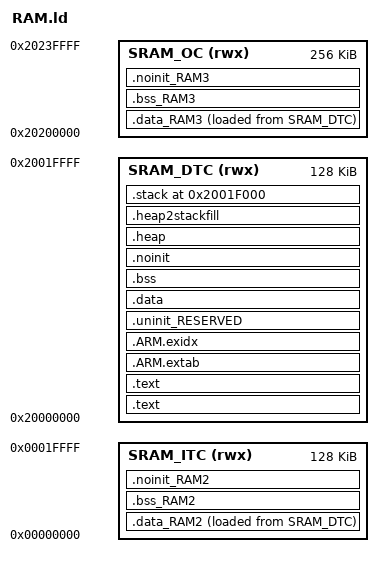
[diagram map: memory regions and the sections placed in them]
/*
 * GENERATED FILE - DO NOT EDIT
 * Copyright (c) 2008-2013 Code Red Technologies Ltd,
 * Copyright 2015, 2018-2019 NXP
 * (c) NXP Semiconductors 2013-2019
 * Generated linker script file for MIMXRT1052xxxxB
 * Created from linkscript.ldt by FMCreateLinkLibraries
 * Using Freemarker v2.3.23
 * MCUXpresso IDE v11.0.0 [Build 2516] [2019-06-05] on Oct 3, 2019 3:25:30 PM
 */

/*
INCLUDE "MIMXRT1052_RAM_Debug_library.ld"
  Created error with: "libcr_newlib_semihost.a"
*/
GROUP (
  "libgcc.a"
  "libc_nano.a"
  "libm.a"
)

/*
INCLUDE "MIMXRT1052_RAM_Debug_memory.ld"
*/
MEMORY
{
  /* Define each memory region */
  SRAM_DTC (rwx) : ORIGIN = 0x20000000, LENGTH = 0x20000 /* 128K bytes (alias RAM) */  
  SRAM_ITC (rwx) : ORIGIN = 0x0, LENGTH = 0x20000 /* 128K bytes (alias RAM2) */  
  SRAM_OC (rwx) : ORIGIN = 0x20200000, LENGTH = 0x40000 /* 256K bytes (alias RAM3) */  
}

  /* Define a symbol for the top of each memory region */
  __base_SRAM_DTC = 0x20000000  ; /* SRAM_DTC */  
  __base_RAM = 0x20000000 ; /* RAM */  
  __top_SRAM_DTC = 0x20000000 + 0x20000 ; /* 128K bytes */  
  __top_RAM = 0x20000000 + 0x20000 ; /* 128K bytes */  
  __base_SRAM_ITC = 0x0  ; /* SRAM_ITC */  
  __base_RAM2 = 0x0 ; /* RAM2 */  
  __top_SRAM_ITC = 0x0 + 0x20000 ; /* 128K bytes */  
  __top_RAM2 = 0x0 + 0x20000 ; /* 128K bytes */  
  __base_SRAM_OC = 0x20200000  ; /* SRAM_OC */  
  __base_RAM3 = 0x20200000 ; /* RAM3 */  
  __top_SRAM_OC = 0x20200000 + 0x40000 ; /* 256K bytes */  
  __top_RAM3 = 0x20200000 + 0x40000 ; /* 256K bytes */  





ENTRY(ResetISR)

SECTIONS
{
     /* MAIN TEXT SECTION */
    .text : ALIGN(4)
    {
        FILL(0xff)
        __vectors_start__ = ABSOLUTE(.) ;
        KEEP(*(.isr_vector))
        /* Global Section Table */
        . = ALIGN(4) ;
        __section_table_start = .;
        __data_section_table = .;
        LONG(LOADADDR(.data));
        LONG(    ADDR(.data));
        LONG(  SIZEOF(.data));
        LONG(LOADADDR(.data_RAM2));
        LONG(    ADDR(.data_RAM2));
        LONG(  SIZEOF(.data_RAM2));
        LONG(LOADADDR(.data_RAM3));
        LONG(    ADDR(.data_RAM3));
        LONG(  SIZEOF(.data_RAM3));
        __data_section_table_end = .;
        __bss_section_table = .;
        LONG(    ADDR(.bss));
        LONG(  SIZEOF(.bss));
        LONG(    ADDR(.bss_RAM2));
        LONG(  SIZEOF(.bss_RAM2));
        LONG(    ADDR(.bss_RAM3));
        LONG(  SIZEOF(.bss_RAM3));
        __bss_section_table_end = .;
        __section_table_end = . ;
        /* End of Global Section Table */

        *(.after_vectors*)

    } > SRAM_DTC

    .text : ALIGN(4)
    {
       *(.text*)
       *(.rodata .rodata.* .constdata .constdata.*)
       . = ALIGN(4);
    } > SRAM_DTC
    /*
     * for exception handling/unwind - some Newlib functions (in common
     * with C++ and STDC++) use this. 
     */
    .ARM.extab : ALIGN(4) 
    {
        *(.ARM.extab* .gnu.linkonce.armextab.*)
    } > SRAM_DTC

    __exidx_start = .;

    .ARM.exidx : ALIGN(4)
    {
        *(.ARM.exidx* .gnu.linkonce.armexidx.*)
    } > SRAM_DTC
    __exidx_end = .;
 
    _etext = .;
        
    /* DATA section for SRAM_ITC */

    .data_RAM2 : ALIGN(4)
    {
        FILL(0xff)
        PROVIDE(__start_data_RAM2 = .) ;
        *(.ramfunc.$RAM2)
        *(.ramfunc.$SRAM_ITC)
        *(.data.$RAM2)
        *(.data.$SRAM_ITC)
        *(.data.$RAM2.*)
        *(.data.$SRAM_ITC.*)
        . = ALIGN(4) ;
        PROVIDE(__end_data_RAM2 = .) ;
     } > SRAM_ITC AT>SRAM_DTC
    /* DATA section for SRAM_OC */

    .data_RAM3 : ALIGN(4)
    {
        FILL(0xff)
        PROVIDE(__start_data_RAM3 = .) ;
        *(.ramfunc.$RAM3)
        *(.ramfunc.$SRAM_OC)
        *(.data.$RAM3)
        *(.data.$SRAM_OC)
        *(.data.$RAM3.*)
        *(.data.$SRAM_OC.*)
        . = ALIGN(4) ;
        PROVIDE(__end_data_RAM3 = .) ;
     } > SRAM_OC AT>SRAM_DTC
    /* MAIN DATA SECTION */
    .uninit_RESERVED (NOLOAD) :
    {
        . = ALIGN(4) ;
        KEEP(*(.bss.$RESERVED*))
       . = ALIGN(4) ;
        _end_uninit_RESERVED = .;
    } > SRAM_DTC

    /* Main DATA section (SRAM_DTC) */
    .data : ALIGN(4)
    {
       FILL(0xff)
       _data = . ;
       *(vtable)
       *(.ramfunc*)
       *(.data*)
       . = ALIGN(4) ;
       _edata = . ;
    } > SRAM_DTC AT>SRAM_DTC

    /* BSS section for SRAM_ITC */
    .bss_RAM2 :
    {
       . = ALIGN(4) ;
       PROVIDE(__start_bss_RAM2 = .) ;
       *(.bss.$RAM2)
       *(.bss.$SRAM_ITC)
       *(.bss.$RAM2.*)
       *(.bss.$SRAM_ITC.*)
       . = ALIGN (. != 0 ? 4 : 1) ; /* avoid empty segment */
       PROVIDE(__end_bss_RAM2 = .) ;
    } > SRAM_ITC

    /* BSS section for SRAM_OC */
    .bss_RAM3 :
    {
       . = ALIGN(4) ;
       PROVIDE(__start_bss_RAM3 = .) ;
       *(.bss.$RAM3)
       *(.bss.$SRAM_OC)
       *(.bss.$RAM3.*)
       *(.bss.$SRAM_OC.*)
       . = ALIGN (. != 0 ? 4 : 1) ; /* avoid empty segment */
       PROVIDE(__end_bss_RAM3 = .) ;
    } > SRAM_OC

    /* MAIN BSS SECTION */
    .bss :
    {
        . = ALIGN(4) ;
        _bss = .;
        *(.bss*)
        *(COMMON)
        . = ALIGN(4) ;
        _ebss = .;
        PROVIDE(end = .);
    } > SRAM_DTC

    /* NOINIT section for SRAM_ITC */
    .noinit_RAM2 (NOLOAD) :
    {
       . = ALIGN(4) ;
       *(.noinit.$RAM2)
       *(.noinit.$SRAM_ITC)
       *(.noinit.$RAM2.*)
       *(.noinit.$SRAM_ITC.*)
       . = ALIGN(4) ;
    } > SRAM_ITC

    /* NOINIT section for SRAM_OC */
    .noinit_RAM3 (NOLOAD) :
    {
       . = ALIGN(4) ;
       *(.noinit.$RAM3)
       *(.noinit.$SRAM_OC)
       *(.noinit.$RAM3.*)
       *(.noinit.$SRAM_OC.*)
       . = ALIGN(4) ;
    } > SRAM_OC

    /* DEFAULT NOINIT SECTION */
    .noinit (NOLOAD):
    {
         . = ALIGN(4) ;
        _noinit = .;
        *(.noinit*)
         . = ALIGN(4) ;
        _end_noinit = .;
    } > SRAM_DTC

    /* Reserve and place Heap within memory map */
    _HeapSize = 0x1000;
    .heap :  ALIGN(4)
    {
        _pvHeapStart = .;
        . += _HeapSize;
        . = ALIGN(4);
        _pvHeapLimit = .;
    } > SRAM_DTC

     _StackSize = 0x1000;
     /* Reserve space in memory for Stack */
    .heap2stackfill  :
    {
        . += _StackSize;
    } > SRAM_DTC
    /* Locate actual Stack in memory map */
    .stack ORIGIN(SRAM_DTC) + LENGTH(SRAM_DTC) - _StackSize - 0:  ALIGN(4)
    {
        _vStackBase = .;
        . = ALIGN(4);
        _vStackTop = . + _StackSize;
    } > SRAM_DTC

    /* Provide basic symbols giving location and size of main text
     * block, including initial values of RW data sections. Note that
     * these will need extending to give a complete picture with
     * complex images (e.g multiple Flash banks).
     */
    _image_start = LOADADDR(.text);
    _image_end = LOADADDR(.data) + SIZEOF(.data);
    _image_size = _image_end - _image_start;
}
